# ESP32S31_RADIO register map
Vendor: Espressif; Series: ESP32-S31; File version: 3.52
Registers are 32-bit, read-write, no defined reset value unless marked. A register's access mark holds for its fields unless they carry their own. Offsets are from the block's base; [hi:lo] are bit positions; {n}, {i} and the like mark numbered series; 'fields as' and 'values as' point back to an identical list.

## MODEM_RADIO_CORE_MID_OBSERVED — Sparse source-qualified word views in the existing owned MMIO aperture; individual meanings and side effects remain unknown.
Base 0x2010A000
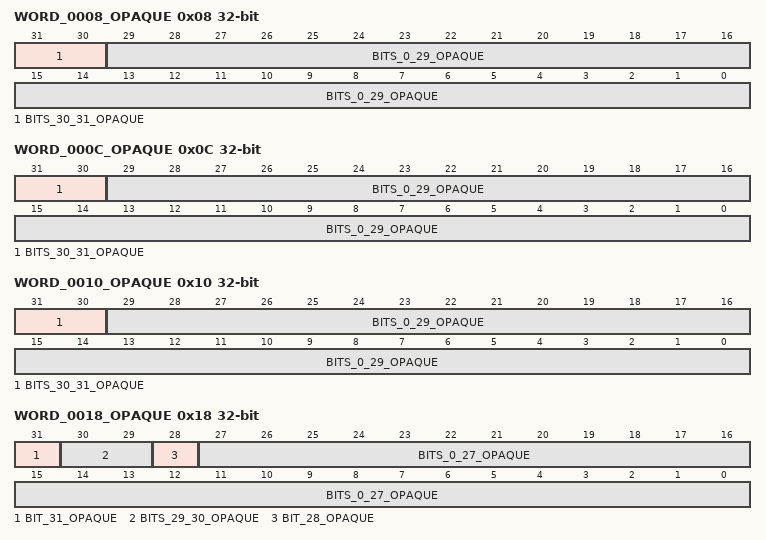
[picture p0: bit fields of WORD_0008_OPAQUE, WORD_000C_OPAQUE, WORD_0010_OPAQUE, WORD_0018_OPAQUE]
0x08 WORD_0008_OPAQUE — Opaque: meaning not established. Aligned 32-bit bus view explicitly addressed by the cited vendor source. No reset or hardware write effect is established.
  [31:30] BITS_30_31_OPAQUE — Opaque: meaning not established. Observed source use; the individual hardware meaning is unknown.
  [29:0] BITS_0_29_OPAQUE — Opaque: meaning not established. Observed source use; the individual hardware meaning is unknown.
0x0C WORD_000C_OPAQUE — Opaque: meaning not established. Aligned 32-bit bus view explicitly addressed by the cited vendor source. No reset or hardware write effect is established.
  fields as WORD_0008_OPAQUE
0x10 WORD_0010_OPAQUE — Opaque: meaning not established. Aligned 32-bit bus view explicitly addressed by the cited vendor source. No reset or hardware write effect is established.
  fields as WORD_0008_OPAQUE
0x14 WORD_0014_OPAQUE — Opaque: meaning not established. Aligned 32-bit bus view explicitly addressed by the cited vendor source. No reset or hardware write effect is established.
  [31:0] BITS_0_31_OPAQUE — Opaque: meaning not established. Observed source use; the individual hardware meaning is unknown.
0x18 WORD_0018_OPAQUE — Opaque: meaning not established. Aligned 32-bit bus view explicitly addressed by the cited vendor source. No reset or hardware write effect is established.
  [31] BIT_31_OPAQUE — Opaque: meaning not established. Observed source use; the individual hardware meaning is unknown.
  [30:29] BITS_29_30_OPAQUE — Opaque: meaning not established. Observed source use; the individual hardware meaning is unknown.
  [28] BIT_28_OPAQUE — Opaque: meaning not established. Observed source use; the individual hardware meaning is unknown.
  [27:0] BITS_0_27_OPAQUE — Opaque: meaning not established. Observed source use; the individual hardware meaning is unknown.
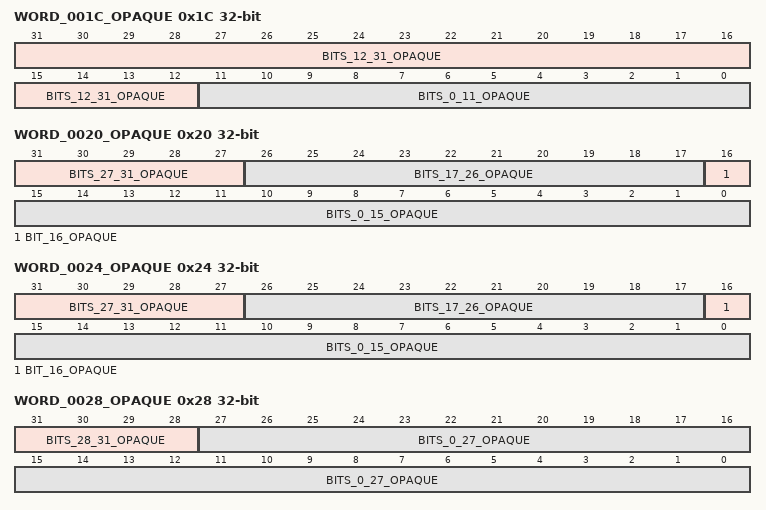
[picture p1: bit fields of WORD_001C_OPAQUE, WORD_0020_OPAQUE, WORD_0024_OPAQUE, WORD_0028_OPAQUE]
0x1C WORD_001C_OPAQUE — Opaque: meaning not established. Aligned 32-bit bus view explicitly addressed by the cited vendor source. No reset or hardware write effect is established.
  [31:12] BITS_12_31_OPAQUE — Opaque: meaning not established. Observed source use; the individual hardware meaning is unknown.
  [11:0] BITS_0_11_OPAQUE — Opaque: meaning not established. Observed source use; the individual hardware meaning is unknown.
0x20 WORD_0020_OPAQUE — Opaque: meaning not established. Aligned 32-bit bus view explicitly addressed by the cited vendor source. No reset or hardware write effect is established.
  [31:27] BITS_27_31_OPAQUE — Opaque: meaning not established. Observed source use; the individual hardware meaning is unknown.
  [26:17] BITS_17_26_OPAQUE — Opaque: meaning not established. Observed source use; the individual hardware meaning is unknown.
  [16] BIT_16_OPAQUE — Opaque: meaning not established. Observed source use; the individual hardware meaning is unknown.
  [15:0] BITS_0_15_OPAQUE — Opaque: meaning not established. Observed source use; the individual hardware meaning is unknown.
0x24 WORD_0024_OPAQUE — Opaque: meaning not established. Aligned 32-bit bus view explicitly addressed by the cited vendor source. No reset or hardware write effect is established.
  fields as WORD_0020_OPAQUE
0x28 WORD_0028_OPAQUE — Opaque: meaning not established. Aligned 32-bit bus view explicitly addressed by the cited vendor source. No reset or hardware write effect is established.
  [31:28] BITS_28_31_OPAQUE — Opaque: meaning not established. Observed source use; the individual hardware meaning is unknown.
  [27:0] BITS_0_27_OPAQUE — Opaque: meaning not established. Observed source use; the individual hardware meaning is unknown.
0x2C WORD_002C_OPAQUE — Opaque: meaning not established. Aligned 32-bit bus view explicitly addressed by the cited vendor source. No reset or hardware write effect is established.
  fields as WORD_0014_OPAQUE
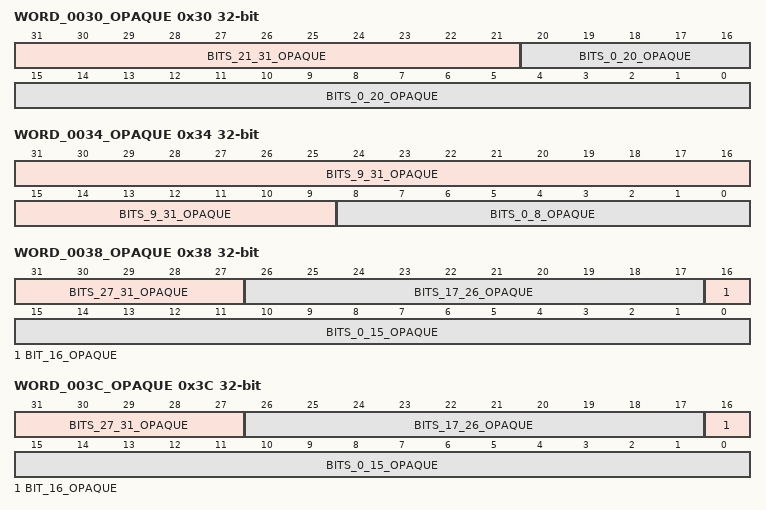
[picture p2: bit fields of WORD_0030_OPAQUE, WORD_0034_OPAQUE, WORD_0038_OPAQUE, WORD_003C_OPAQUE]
0x30 WORD_0030_OPAQUE — Opaque: meaning not established. Aligned 32-bit bus view explicitly addressed by the cited vendor source. No reset or hardware write effect is established.
  [31:21] BITS_21_31_OPAQUE — Opaque: meaning not established. Observed source use; the individual hardware meaning is unknown.
  [20:0] BITS_0_20_OPAQUE — Opaque: meaning not established. Observed source use; the individual hardware meaning is unknown.
0x34 WORD_0034_OPAQUE — Opaque: meaning not established. Aligned 32-bit bus view explicitly addressed by the cited vendor source. No reset or hardware write effect is established.
  [31:9] BITS_9_31_OPAQUE — Opaque: meaning not established. Observed source use; the individual hardware meaning is unknown.
  [8:0] BITS_0_8_OPAQUE — Opaque: meaning not established. Observed source use; the individual hardware meaning is unknown.
0x38 WORD_0038_OPAQUE — Opaque: meaning not established. Aligned 32-bit bus view explicitly addressed by the cited vendor source. No reset or hardware write effect is established.
  fields as WORD_0020_OPAQUE
0x3C WORD_003C_OPAQUE — Opaque: meaning not established. Aligned 32-bit bus view explicitly addressed by the cited vendor source. No reset or hardware write effect is established.
  fields as WORD_0020_OPAQUE
0x40 WORD_0040_OPAQUE — Opaque: meaning not established. Aligned 32-bit bus view explicitly addressed by the cited vendor source. No reset or hardware write effect is established.
  fields as WORD_0014_OPAQUE
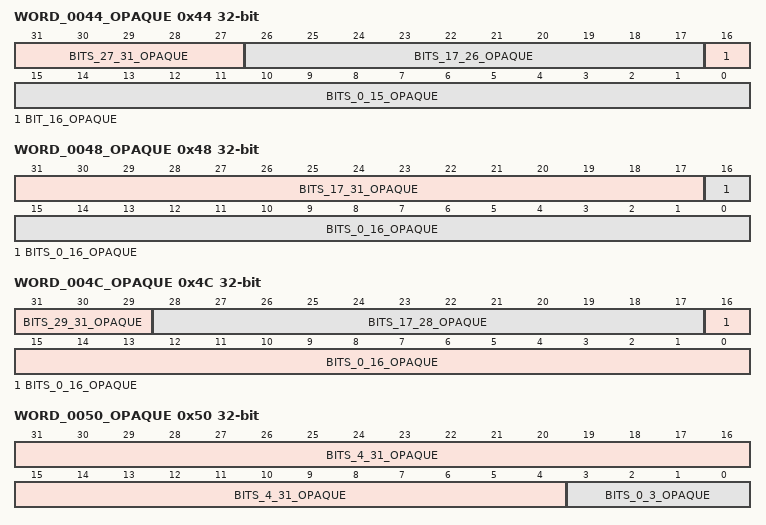
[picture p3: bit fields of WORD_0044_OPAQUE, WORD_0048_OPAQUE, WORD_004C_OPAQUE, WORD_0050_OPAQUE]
0x44 WORD_0044_OPAQUE — Opaque: meaning not established. Aligned 32-bit bus view explicitly addressed by the cited vendor source. No reset or hardware write effect is established.
  fields as WORD_0020_OPAQUE
0x48 WORD_0048_OPAQUE — Opaque: meaning not established. Aligned 32-bit bus view explicitly addressed by the cited vendor source. No reset or hardware write effect is established.
  [31:17] BITS_17_31_OPAQUE — Opaque: meaning not established. Observed source use; the individual hardware meaning is unknown.
  [16:0] BITS_0_16_OPAQUE — Opaque: meaning not established. Observed source use; the individual hardware meaning is unknown.
0x4C WORD_004C_OPAQUE — Opaque: meaning not established. Aligned 32-bit bus view explicitly addressed by the cited vendor source. No reset or hardware write effect is established.
  [31:29] BITS_29_31_OPAQUE — Opaque: meaning not established. Observed source use; the individual hardware meaning is unknown.
  [28:17] BITS_17_28_OPAQUE — Opaque: meaning not established. Observed source use; the individual hardware meaning is unknown.
  [16:0] BITS_0_16_OPAQUE — Opaque: meaning not established. Observed source use; the individual hardware meaning is unknown.
0x50 WORD_0050_OPAQUE — Opaque: meaning not established. Aligned 32-bit bus view explicitly addressed by the cited vendor source. No reset or hardware write effect is established.
  [31:4] BITS_4_31_OPAQUE — Opaque: meaning not established. Observed source use; the individual hardware meaning is unknown.
  [3:0] BITS_0_3_OPAQUE — Opaque: meaning not established. Observed source use; the individual hardware meaning is unknown.
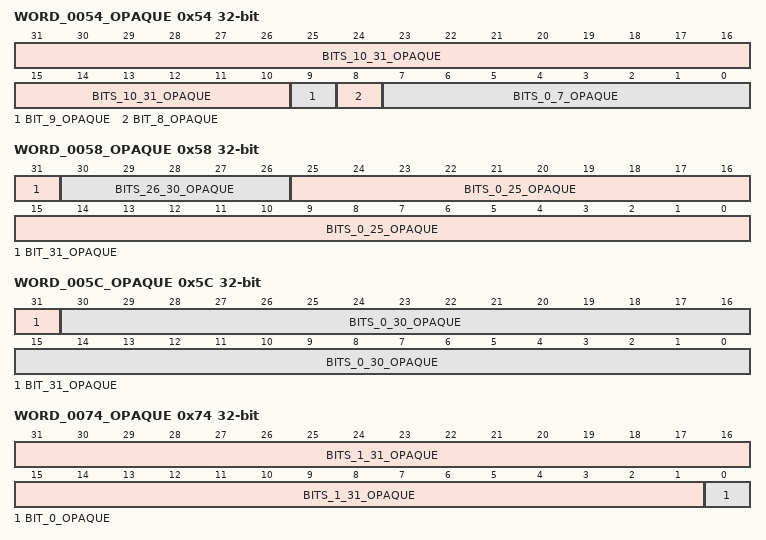
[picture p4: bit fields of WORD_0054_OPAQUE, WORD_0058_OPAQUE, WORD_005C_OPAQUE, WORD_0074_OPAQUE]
0x54 WORD_0054_OPAQUE — Opaque: meaning not established. Aligned 32-bit bus view explicitly addressed by the cited vendor source. No reset or hardware write effect is established.
  [31:10] BITS_10_31_OPAQUE — Opaque: meaning not established. Observed source use; the individual hardware meaning is unknown.
  [9] BIT_9_OPAQUE — Opaque: meaning not established. Observed source use; the individual hardware meaning is unknown.
  [8] BIT_8_OPAQUE — Opaque: meaning not established. Observed source use; the individual hardware meaning is unknown.
  [7:0] BITS_0_7_OPAQUE — Opaque: meaning not established. Observed source use; the individual hardware meaning is unknown.
0x58 WORD_0058_OPAQUE — Opaque: meaning not established. Aligned 32-bit bus view explicitly addressed by the cited vendor source. No reset or hardware write effect is established.
  [31] BIT_31_OPAQUE — Opaque: meaning not established. Observed source use; the individual hardware meaning is unknown.
  [30:26] BITS_26_30_OPAQUE — Opaque: meaning not established. Observed source use; the individual hardware meaning is unknown.
  [25:0] BITS_0_25_OPAQUE — Opaque: meaning not established. Observed source use; the individual hardware meaning is unknown.
0x5C WORD_005C_OPAQUE — Opaque: meaning not established. Aligned 32-bit bus view explicitly addressed by the cited vendor source. No reset or hardware write effect is established.
  [31] BIT_31_OPAQUE — Opaque: meaning not established. Observed source use; the individual hardware meaning is unknown.
  [30:0] BITS_0_30_OPAQUE — Opaque: meaning not established. Observed source use; the individual hardware meaning is unknown.
0x60 WORD_0060_OPAQUE — Opaque: meaning not established. Aligned 32-bit bus view explicitly addressed by the cited vendor source. No reset or hardware write effect is established.
  fields as WORD_0014_OPAQUE
0x64 WORD_0064_OPAQUE — Opaque: meaning not established. Aligned 32-bit bus view explicitly addressed by the cited vendor source. No reset or hardware write effect is established.
  fields as WORD_0014_OPAQUE
0x68 WORD_0068_OPAQUE — Opaque: meaning not established. Aligned 32-bit bus view explicitly addressed by the cited vendor source. No reset or hardware write effect is established.
  fields as WORD_0014_OPAQUE
0x6C WORD_006C_OPAQUE — Opaque: meaning not established. Aligned 32-bit bus view explicitly addressed by the cited vendor source. No reset or hardware write effect is established.
  fields as WORD_0014_OPAQUE
0x70 WORD_0070_OPAQUE — Opaque: meaning not established. Aligned 32-bit bus view explicitly addressed by the cited vendor source. No reset or hardware write effect is established.
  fields as WORD_0014_OPAQUE
0x74 WORD_0074_OPAQUE — Opaque: meaning not established. Aligned 32-bit bus view explicitly addressed by the cited vendor source. No reset or hardware write effect is established.
  [31:1] BITS_1_31_OPAQUE — Opaque: meaning not established. Observed source use; the individual hardware meaning is unknown.
  [0] BIT_0_OPAQUE — Opaque: meaning not established. Observed source use; the individual hardware meaning is unknown.
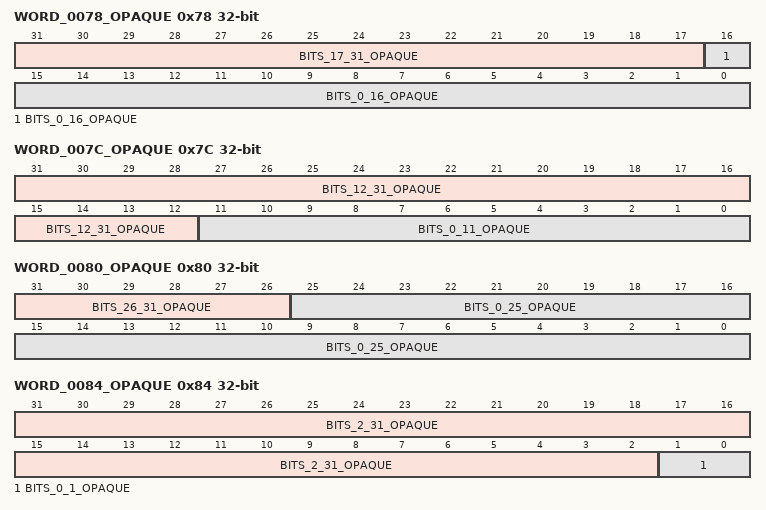
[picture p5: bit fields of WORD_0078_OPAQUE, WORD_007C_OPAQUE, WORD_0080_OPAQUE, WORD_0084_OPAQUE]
0x78 WORD_0078_OPAQUE — Opaque: meaning not established. Aligned 32-bit bus view explicitly addressed by the cited vendor source. No reset or hardware write effect is established.
  fields as WORD_0048_OPAQUE
0x7C WORD_007C_OPAQUE — Opaque: meaning not established. Aligned 32-bit bus view explicitly addressed by the cited vendor source. No reset or hardware write effect is established.
  fields as WORD_001C_OPAQUE
0x80 WORD_0080_OPAQUE — Opaque: meaning not established. Aligned 32-bit bus view explicitly addressed by the cited vendor source. No reset or hardware write effect is established.
  [31:26] BITS_26_31_OPAQUE — Opaque: meaning not established. Observed source use; the individual hardware meaning is unknown.
  [25:0] BITS_0_25_OPAQUE — Opaque: meaning not established. Observed source use; the individual hardware meaning is unknown.
0x84 WORD_0084_OPAQUE — Opaque: meaning not established. Aligned 32-bit bus view explicitly addressed by the cited vendor source. No reset or hardware write effect is established.
  [31:2] BITS_2_31_OPAQUE — Opaque: meaning not established. Observed source use; the individual hardware meaning is unknown.
  [1:0] BITS_0_1_OPAQUE — Opaque: meaning not established. Observed source use; the individual hardware meaning is unknown.
0xF4 WORD_00F4_OPAQUE — Opaque: meaning not established. Aligned 32-bit bus view explicitly addressed by the cited vendor source. No reset or hardware write effect is established.
  [0] BIT_0_OPAQUE — Opaque: meaning not established. Observed source use; the individual hardware meaning is unknown.
0x1F8 WORD_01F8_OPAQUE — Opaque: meaning not established. Aligned 32-bit bus view explicitly addressed by the cited vendor source. No reset or hardware write effect is established.
  fields as WORD_00F4_OPAQUE
0x7FC WORD_07FC_OPAQUE — Opaque: meaning not established. Aligned 32-bit bus view explicitly addressed by the cited vendor source. No reset or hardware write effect is established.
  [27:0] BITS_0_27_OPAQUE — Opaque: meaning not established. Observed source use; the individual hardware meaning is unknown.
0x804 WORD_0804_OPAQUE — Opaque: meaning not established. Aligned 32-bit bus view explicitly addressed by the cited vendor source. No reset or hardware write effect is established.
  fields as WORD_0014_OPAQUE
0x808 WORD_0808_OPAQUE — Opaque: meaning not established. Aligned 32-bit bus view explicitly addressed by the cited vendor source. No reset or hardware write effect is established.
  fields as WORD_0014_OPAQUE
{0x30C+0x10*i} WORD_{i:03}C_OPAQUE (i=80..82) — Opaque: meaning not established. Aligned 32-bit bus view explicitly addressed by the cited vendor source. No reset or hardware write effect is established.
  fields as WORD_0014_OPAQUE
0x810 WORD_0810_OPAQUE — Opaque: meaning not established. Aligned 32-bit bus view explicitly addressed by the cited vendor source. No reset or hardware write effect is established.
  fields as WORD_0014_OPAQUE
0x814 WORD_0814_OPAQUE — Opaque: meaning not established. Aligned 32-bit bus view explicitly addressed by the cited vendor source. No reset or hardware write effect is established.
  fields as WORD_0014_OPAQUE
0x818 WORD_0818_OPAQUE — Opaque: meaning not established. Aligned 32-bit bus view explicitly addressed by the cited vendor source. No reset or hardware write effect is established.
  [15:0] BITS_0_15_OPAQUE — Opaque: meaning not established. Observed source use; the individual hardware meaning is unknown.
0x824 WORD_0824_OPAQUE — Opaque: meaning not established. Aligned 32-bit bus view explicitly addressed by the cited vendor source. No reset or hardware write effect is established.
  fields as WORD_0014_OPAQUE
0x828 WORD_0828_OPAQUE — Opaque: meaning not established. Aligned 32-bit bus view explicitly addressed by the cited vendor source. No reset or hardware write effect is established.
  fields as WORD_0014_OPAQUE
0x830 WORD_0830_OPAQUE — Opaque: meaning not established. Aligned 32-bit bus view explicitly addressed by the cited vendor source. No reset or hardware write effect is established.
  fields as WORD_0014_OPAQUE
0x834 WORD_0834_OPAQUE — Opaque: meaning not established. Aligned 32-bit bus view explicitly addressed by the cited vendor source. No reset or hardware write effect is established.
  fields as WORD_0014_OPAQUE
0x838 WORD_0838_OPAQUE — Opaque: meaning not established. Aligned 32-bit bus view explicitly addressed by the cited vendor source. No reset or hardware write effect is established.
  fields as WORD_0818_OPAQUE
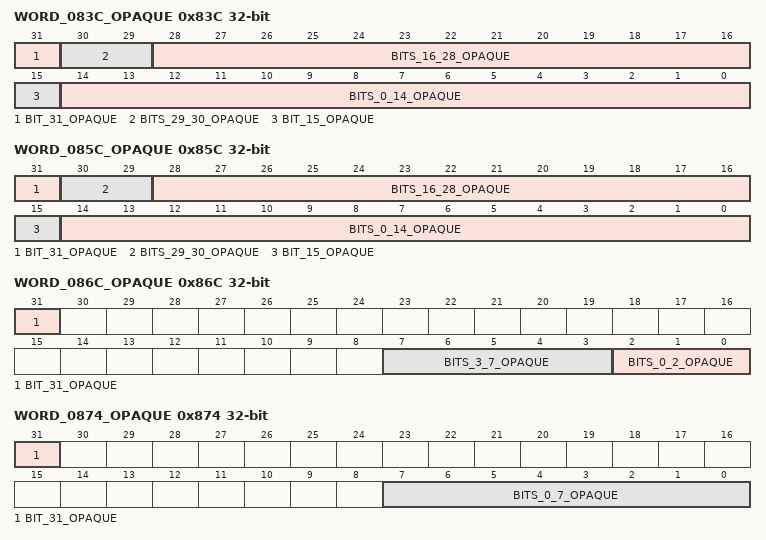
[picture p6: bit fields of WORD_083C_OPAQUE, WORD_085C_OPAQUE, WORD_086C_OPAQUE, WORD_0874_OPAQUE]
0x83C WORD_083C_OPAQUE — Opaque: meaning not established. Aligned 32-bit bus view explicitly addressed by the cited vendor source. No reset or hardware write effect is established.
  [31] BIT_31_OPAQUE — Opaque: meaning not established. Observed source use; the individual hardware meaning is unknown.
  [30:29] BITS_29_30_OPAQUE — Opaque: meaning not established. Observed source use; the individual hardware meaning is unknown.
  [28:16] BITS_16_28_OPAQUE — Opaque: meaning not established. Observed source use; the individual hardware meaning is unknown.
  [15] BIT_15_OPAQUE — Opaque: meaning not established. Observed source use; the individual hardware meaning is unknown.
  [14:0] BITS_0_14_OPAQUE — Opaque: meaning not established. Observed source use; the individual hardware meaning is unknown.
0x844 WORD_0844_OPAQUE — Opaque: meaning not established. Aligned 32-bit bus view explicitly addressed by the cited vendor source. No reset or hardware write effect is established.
  fields as WORD_0014_OPAQUE
0x848 WORD_0848_OPAQUE — Opaque: meaning not established. Aligned 32-bit bus view explicitly addressed by the cited vendor source. No reset or hardware write effect is established.
  fields as WORD_0014_OPAQUE
0x84C WORD_084C_OPAQUE — Opaque: meaning not established. Aligned 32-bit bus view explicitly addressed by the cited vendor source. No reset or hardware write effect is established.
  fields as WORD_0014_OPAQUE
0x850 WORD_0850_OPAQUE — Opaque: meaning not established. Aligned 32-bit bus view explicitly addressed by the cited vendor source. No reset or hardware write effect is established.
  fields as WORD_0014_OPAQUE
0x854 WORD_0854_OPAQUE — Opaque: meaning not established. Aligned 32-bit bus view explicitly addressed by the cited vendor source. No reset or hardware write effect is established.
  fields as WORD_0014_OPAQUE
0x858 WORD_0858_OPAQUE — Opaque: meaning not established. Aligned 32-bit bus view explicitly addressed by the cited vendor source. No reset or hardware write effect is established.
  fields as WORD_0818_OPAQUE
0x85C WORD_085C_OPAQUE — Opaque: meaning not established. Aligned 32-bit bus view explicitly addressed by the cited vendor source. No reset or hardware write effect is established.
  fields as WORD_083C_OPAQUE
0x860 WORD_0860_OPAQUE — Opaque: meaning not established. Aligned 32-bit bus view explicitly addressed by the cited vendor source. No reset or hardware write effect is established.
  [23:0] BITS_0_23_OPAQUE — Opaque: meaning not established. Observed source use; the individual hardware meaning is unknown.
0x864 WORD_0864_OPAQUE — Opaque: meaning not established. Aligned 32-bit bus view explicitly addressed by the cited vendor source. No reset or hardware write effect is established.
  [11:0] BITS_0_11_OPAQUE — Opaque: meaning not established. Observed source use; the individual hardware meaning is unknown.
0x868 WORD_0868_OPAQUE — Opaque: meaning not established. Aligned 32-bit bus view explicitly addressed by the cited vendor source. No reset or hardware write effect is established.
  fields as WORD_0014_OPAQUE
0x86C WORD_086C_OPAQUE — Opaque: meaning not established. Aligned 32-bit bus view explicitly addressed by the cited vendor source. No reset or hardware write effect is established.
  [31] BIT_31_OPAQUE — Opaque: meaning not established. Observed source use; the individual hardware meaning is unknown.
  [7:3] BITS_3_7_OPAQUE — Opaque: meaning not established. Observed source use; the individual hardware meaning is unknown.
  [2:0] BITS_0_2_OPAQUE — Opaque: meaning not established. Observed source use; the individual hardware meaning is unknown.
0x870 WORD_0870_OPAQUE — Opaque: meaning not established. Aligned 32-bit bus view explicitly addressed by the cited vendor source. No reset or hardware write effect is established.
  fields as WORD_0014_OPAQUE
0x874 WORD_0874_OPAQUE — Opaque: meaning not established. Aligned 32-bit bus view explicitly addressed by the cited vendor source. No reset or hardware write effect is established.
  [31] BIT_31_OPAQUE — Opaque: meaning not established. Observed source use; the individual hardware meaning is unknown.
  [7:0] BITS_0_7_OPAQUE — Opaque: meaning not established. Observed source use; the individual hardware meaning is unknown.
0x878 WORD_0878_OPAQUE — Opaque: meaning not established. Aligned 32-bit bus view explicitly addressed by the cited vendor source. No reset or hardware write effect is established.
  fields as WORD_0014_OPAQUE
0x87C WORD_087C_OPAQUE — Opaque: meaning not established. Aligned 32-bit bus view explicitly addressed by the cited vendor source. No reset or hardware write effect is established.
  [14:0] BITS_0_14_OPAQUE — Opaque: meaning not established. Observed source use; the individual hardware meaning is unknown.
0x880 WORD_0880_OPAQUE — Opaque: meaning not established. Aligned 32-bit bus view explicitly addressed by the cited vendor source. No reset or hardware write effect is established.
  fields as WORD_0818_OPAQUE
0x884 WORD_0884_OPAQUE — Opaque: meaning not established. Aligned 32-bit bus view explicitly addressed by the cited vendor source. No reset or hardware write effect is established.
  [7:0] BITS_0_7_OPAQUE — Opaque: meaning not established. Observed source use; the individual hardware meaning is unknown.
0x888 WORD_0888_OPAQUE — Opaque: meaning not established. Aligned 32-bit bus view explicitly addressed by the cited vendor source. No reset or hardware write effect is established.
  fields as WORD_087C_OPAQUE
0x88C WORD_088C_OPAQUE — Opaque: meaning not established. Aligned 32-bit bus view explicitly addressed by the cited vendor source. No reset or hardware write effect is established.
  fields as WORD_087C_OPAQUE
0x890 WORD_0890_OPAQUE — Opaque: meaning not established. Aligned 32-bit bus view explicitly addressed by the cited vendor source. No reset or hardware write effect is established.
  fields as WORD_0014_OPAQUE
0x894 WORD_0894_OPAQUE — Opaque: meaning not established. Aligned 32-bit bus view explicitly addressed by the cited vendor source. No reset or hardware write effect is established.
  fields as WORD_087C_OPAQUE
0x898 WORD_0898_OPAQUE — Opaque: meaning not established. Aligned 32-bit bus view explicitly addressed by the cited vendor source. No reset or hardware write effect is established.
  [3:0] BITS_0_3_OPAQUE — Opaque: meaning not established. Observed source use; the individual hardware meaning is unknown.
0x89C WORD_089C_OPAQUE — Opaque: meaning not established. Aligned 32-bit bus view explicitly addressed by the cited vendor source. No reset or hardware write effect is established.
  fields as WORD_0898_OPAQUE
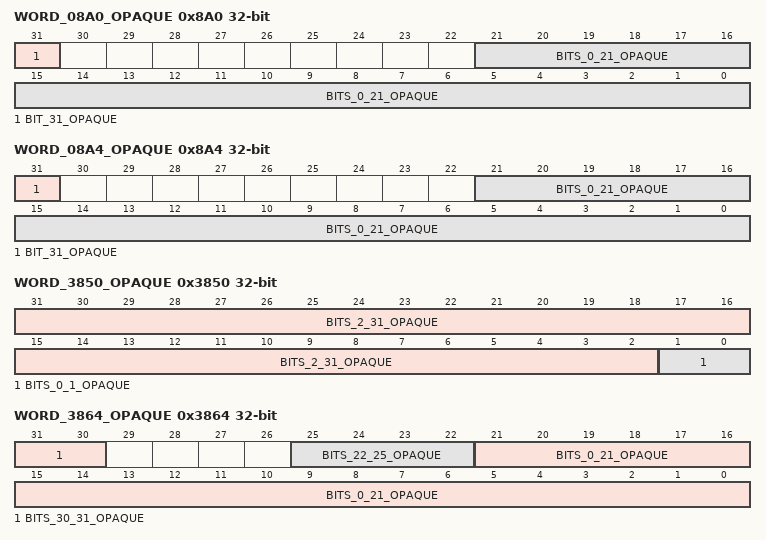
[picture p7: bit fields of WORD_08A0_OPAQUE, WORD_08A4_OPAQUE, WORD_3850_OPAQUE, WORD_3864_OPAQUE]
0x8A0 WORD_08A0_OPAQUE — Opaque: meaning not established. Aligned 32-bit bus view explicitly addressed by the cited vendor source. No reset or hardware write effect is established.
  [31] BIT_31_OPAQUE — Opaque: meaning not established. Observed source use; the individual hardware meaning is unknown.
  [21:0] BITS_0_21_OPAQUE — Opaque: meaning not established. Observed source use; the individual hardware meaning is unknown.
0x8A4 WORD_08A4_OPAQUE — Opaque: meaning not established. Aligned 32-bit bus view explicitly addressed by the cited vendor source. No reset or hardware write effect is established.
  fields as WORD_08A0_OPAQUE
0x8A8 WORD_08A8_OPAQUE — Opaque: meaning not established. Aligned 32-bit bus view explicitly addressed by the cited vendor source. No reset or hardware write effect is established.
  fields as WORD_0014_OPAQUE
0xFF8 WORD_0FF8_OPAQUE — Opaque: meaning not established. Aligned 32-bit bus view explicitly addressed by the cited vendor source. No reset or hardware write effect is established.
  fields as WORD_00F4_OPAQUE
0xFFC WORD_0FFC_OPAQUE — Opaque: meaning not established. Aligned 32-bit bus view explicitly addressed by the cited vendor source. No reset or hardware write effect is established.
  fields as WORD_07FC_OPAQUE
0x3848 WORD_3848_OPAQUE — Opaque: meaning not established. Aligned 32-bit bus view explicitly addressed by the cited vendor source. No reset or hardware write effect is established.
  fields as WORD_0014_OPAQUE
0x3850 WORD_3850_OPAQUE ro — Opaque: meaning not established. Aligned 32-bit bus view explicitly addressed by the cited vendor source. No reset or hardware write effect is established.
  fields as WORD_0084_OPAQUE
0x3864 WORD_3864_OPAQUE — Opaque: meaning not established. Aligned 32-bit bus view explicitly addressed by the cited vendor source. No reset or hardware write effect is established.
  [31:30] BITS_30_31_OPAQUE — Opaque: meaning not established. Observed source use; the individual hardware meaning is unknown.
  [25:22] BITS_22_25_OPAQUE — Opaque: meaning not established. Observed source use; the individual hardware meaning is unknown.
  [21:0] BITS_0_21_OPAQUE — Opaque: meaning not established. Observed source use; the individual hardware meaning is unknown.
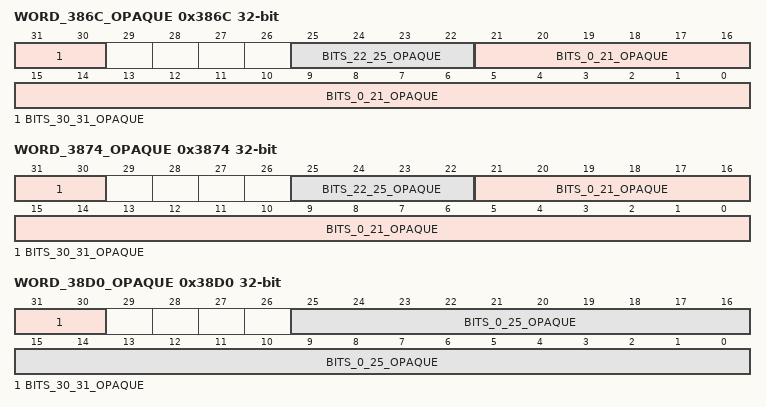
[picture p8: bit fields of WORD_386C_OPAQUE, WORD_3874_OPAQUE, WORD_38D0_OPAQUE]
0x386C WORD_386C_OPAQUE — Opaque: meaning not established. Aligned 32-bit bus view explicitly addressed by the cited vendor source. No reset or hardware write effect is established.
  fields as WORD_3864_OPAQUE
0x3874 WORD_3874_OPAQUE — Opaque: meaning not established. Aligned 32-bit bus view explicitly addressed by the cited vendor source. No reset or hardware write effect is established.
  fields as WORD_3864_OPAQUE
0x38D0 WORD_38D0_OPAQUE — Opaque: meaning not established. Aligned 32-bit bus view explicitly addressed by the cited vendor source. No reset or hardware write effect is established.
  [31:30] BITS_30_31_OPAQUE — Opaque: meaning not established. Observed source use; the individual hardware meaning is unknown.
  [25:0] BITS_0_25_OPAQUE — Opaque: meaning not established. Observed source use; the individual hardware meaning is unknown.
